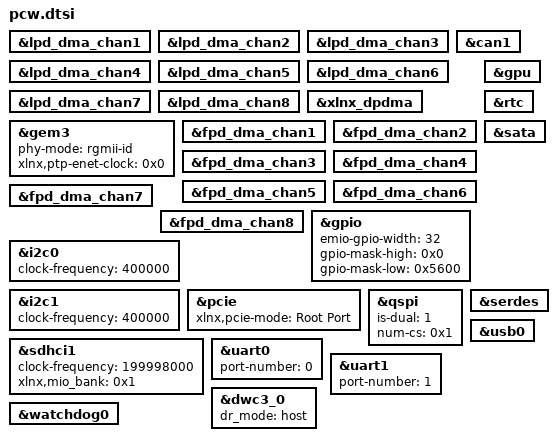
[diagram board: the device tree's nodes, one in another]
/*
 * CAUTION: This file is automatically generated by Xilinx.
 * Version:  
 * Today is: Tue Apr 25 21:50:02 2017
*/


&lpd_dma_chan1 {
	status = "okay";
};
&lpd_dma_chan2 {
	status = "okay";
};
&lpd_dma_chan3 {
	status = "okay";
};
&lpd_dma_chan4 {
	status = "okay";
};
&lpd_dma_chan5 {
	status = "okay";
};
&lpd_dma_chan6 {
	status = "okay";
};
&lpd_dma_chan7 {
	status = "okay";
};
&lpd_dma_chan8 {
	status = "okay";
};
&can1 {
	status = "okay";
};
&xlnx_dpdma {
	status = "okay";
};
&gem3 {
	phy-mode = "rgmii-id";
	status = "okay";
	xlnx,ptp-enet-clock = <0x0>;
};
&fpd_dma_chan1 {
	status = "okay";
};
&fpd_dma_chan2 {
	status = "okay";
};
&fpd_dma_chan3 {
	status = "okay";
};
&fpd_dma_chan4 {
	status = "okay";
};
&fpd_dma_chan5 {
	status = "okay";
};
&fpd_dma_chan6 {
	status = "okay";
};
&fpd_dma_chan7 {
	status = "okay";
};
&fpd_dma_chan8 {
	status = "okay";
};
&gpio {
	emio-gpio-width = <32>;
	gpio-mask-high = <0x0>;
	gpio-mask-low = <0x5600>;
	status = "okay";
};
&gpu {
	status = "okay";
};
&i2c0 {
	clock-frequency = <400000>;
	status = "okay";
};
&i2c1 {
	clock-frequency = <400000>;
	status = "okay";
};
&pcie {
	status = "okay";
	xlnx,pcie-mode = "Root Port";
};
&qspi {
	is-dual = <1>;
	num-cs = <0x1>;
	status = "okay";
};
&rtc {
	status = "okay";
};
&sata {
	status = "okay";
};
&sdhci1 {
	clock-frequency = <199998000>;
	status = "okay";
	xlnx,mio_bank = <0x1>;
};
&serdes {
	status = "okay";
};
&uart0 {
	device_type = "serial";
	port-number = <0>;
	status = "okay";
};
&uart1 {
	device_type = "serial";
	port-number = <1>;
	status = "okay";
};
&dwc3_0 {
	dr_mode = "host";
	status = "okay";
};
&watchdog0 {
	status = "okay";
};
&usb0 {
	status = "okay";
};
